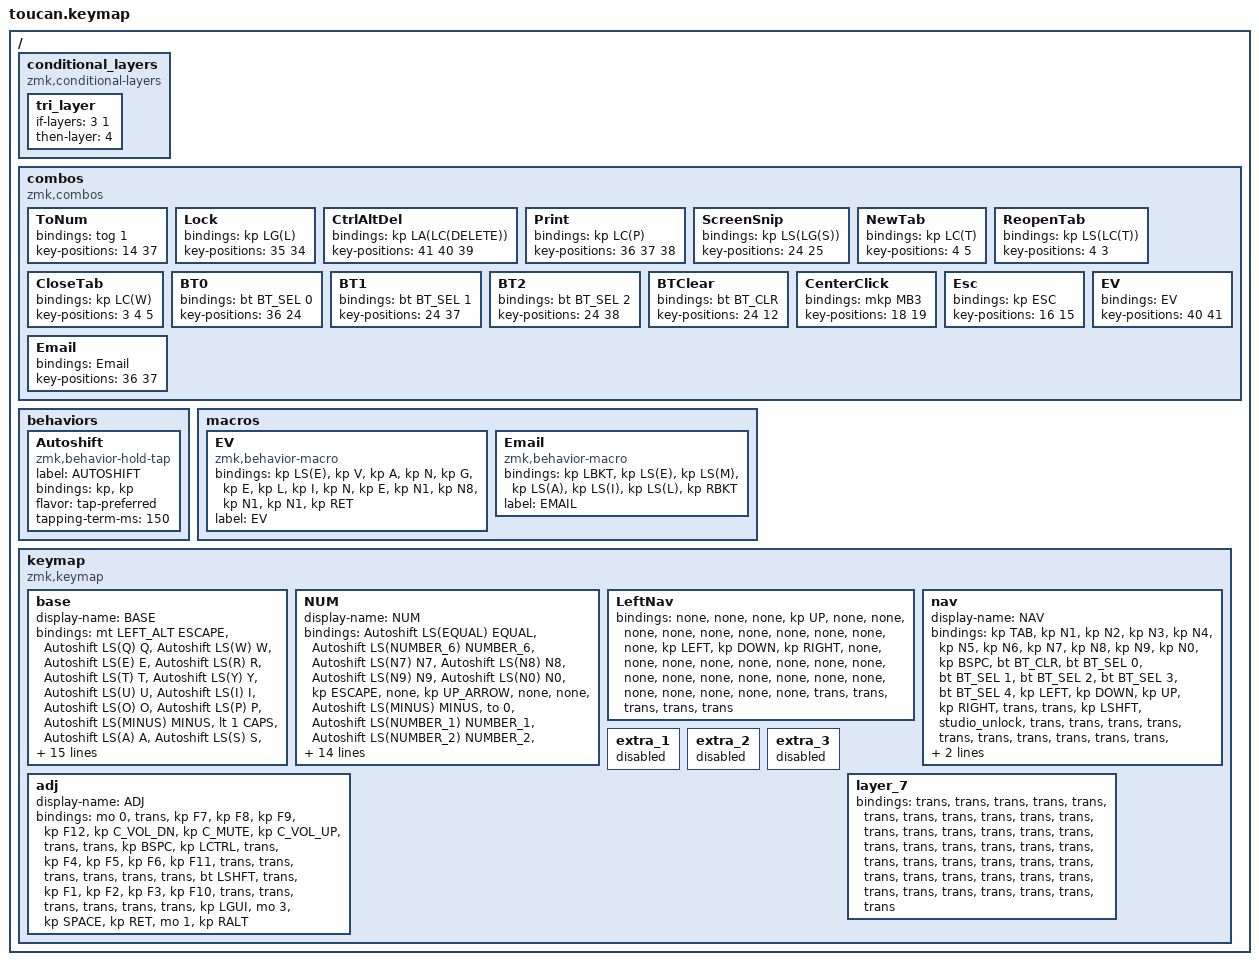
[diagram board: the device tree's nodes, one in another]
#include <behaviors.dtsi>
#include <dt-bindings/zmk/bt.h>
#include <dt-bindings/zmk/keys.h>
#include <dt-bindings/zmk/pointing.h>

#define BASE 0
#define NAV  1
#define SYM  2
#define ADJ  3

/ {
    conditional_layers {
        compatible = "zmk,conditional-layers";

        tri_layer {
            if-layers = <3 1>;
            then-layer = <4>;
        };
    };

    combos {
        compatible = "zmk,combos";

        ToNum {
            bindings = <&tog 1>;
            key-positions = <14 37>;
        };

        Lock {
            bindings = <&kp LG(L)>;
            key-positions = <35 34>;
        };

        CtrlAltDel {
            bindings = <&kp LA(LC(DELETE))>;
            key-positions = <41 40 39>;
        };

        Print {
            bindings = <&kp LC(P)>;
            key-positions = <36 37 38>;
        };

        ScreenSnip {
            bindings = <&kp LS(LG(S))>;
            key-positions = <24 25>;
        };

        NewTab {
            bindings = <&kp LC(T)>;
            key-positions = <4 5>;
        };

        ReopenTab {
            bindings = <&kp LS(LC(T))>;
            key-positions = <4 3>;
        };

        CloseTab {
            bindings = <&kp LC(W)>;
            key-positions = <3 4 5>;
        };

        BT0 {
            bindings = <&bt BT_SEL 0>;
            key-positions = <36 24>;
        };

        BT1 {
            bindings = <&bt BT_SEL 1>;
            key-positions = <24 37>;
        };

        BT2 {
            bindings = <&bt BT_SEL 2>;
            key-positions = <24 38>;
        };

        BTClear {
            bindings = <&bt BT_CLR>;
            key-positions = <24 12>;
        };

        CenterClick {
            bindings = <&mkp MB3>;
            key-positions = <18 19>;
        };

        Esc {
            bindings = <&kp ESC>;
            key-positions = <16 15>;
        };

        EV {
            bindings = <&EV>;
            key-positions = <40 41>;
        };

        Email {
            bindings = <&Email>;
            key-positions = <36 37>;
        };
    };

    behaviors {
        Autoshift: Autoshift {
            compatible = "zmk,behavior-hold-tap";
            label = "AUTOSHIFT";
            bindings = <&kp>, <&kp>;

            #binding-cells = <2>;
            flavor = "tap-preferred";
            tapping-term-ms = <150>;
        };
    };

    macros {
        EV: EV {
            compatible = "zmk,behavior-macro";
            #binding-cells = <0>;
            bindings = <&kp LS(E) &kp V &kp A &kp N &kp G &kp E &kp L &kp I &kp N &kp E &kp N1 &kp N8 &kp N1 &kp N1 &kp RET>;
            label = "EV";
        };

        Email: Email {
            compatible = "zmk,behavior-macro";
            #binding-cells = <0>;
            bindings = <&kp LBKT &kp LS(E) &kp LS(M) &kp LS(A) &kp LS(I) &kp LS(L) &kp RBKT>;
            label = "EMAIL";
        };
    };

    keymap {
        compatible = "zmk,keymap";

        base {
            display-name = "BASE";
            bindings = <
&mt LEFT_ALT ESCAPE  &Autoshift LS(Q) Q  &Autoshift LS(W) W  &Autoshift LS(E) E  &Autoshift LS(R) R  &Autoshift LS(T) T  &Autoshift LS(Y) Y  &Autoshift LS(U) U  &Autoshift LS(I) I  &Autoshift LS(O) O  &Autoshift LS(P) P  &Autoshift LS(MINUS) MINUS  &lt 1 CAPS  &Autoshift LS(A) A  &Autoshift LS(S) S  &Autoshift LS(D) D  &Autoshift LS(F) F  &Autoshift LS(G) G  &Autoshift LS(H) H  &Autoshift LS(J) J  &Autoshift LS(K) K  &Autoshift LS(L) L  &Autoshift LS(SEMI) SEMICOLON  &Autoshift LS(SQT) SQT  &kp LEFT_SHIFT  &Autoshift LS(Z) Z  &Autoshift LS(X) X  &Autoshift LS(C) C  &Autoshift LS(V) V  &Autoshift LS(B) B  &Autoshift LS(N) N  &Autoshift LS(M) M  &Autoshift LS(COMMA) COMMA  &Autoshift LS(DOT) PERIOD  &Autoshift LS(FSLH) SLASH  &sk LC(LEFT_SHIFT)  &kp LCTRL  &kp BACKSPACE  &kp DELETE  &mt LEFT_GUI ENTER  &kp SPACE  &mt LS(TAB) TAB
            >;
        };

        NUM {
            display-name = "NUM";
            bindings = <
&Autoshift LS(EQUAL) EQUAL  &Autoshift LS(NUMBER_6) NUMBER_6  &Autoshift LS(N7) N7  &Autoshift LS(N8) N8  &Autoshift LS(N9) N9  &Autoshift LS(N0) N0  &kp ESCAPE  &none  &kp UP_ARROW  &none  &none  &Autoshift LS(MINUS) MINUS  &to 0  &Autoshift LS(NUMBER_1) NUMBER_1  &Autoshift LS(NUMBER_2) NUMBER_2  &Autoshift LS(NUMBER_3) NUMBER_3  &Autoshift LS(NUMBER_4) NUMBER_4  &Autoshift LS(N5) N5  &none  &kp LEFT  &kp DOWN  &kp RIGHT  &Autoshift LS(SEMICOLON) SEMICOLON  &Autoshift LS(APOSTROPHE) SQT  &kp LSHFT  &mt MINUS SLASH  &mt MINUS SLASH  &mt MINUS SLASH  &mt RIGHT_BRACKET LEFT_BRACKET  &mt RIGHT_BRACKET LEFT_BRACKET  &kp ESC  &none  &Autoshift LS(COMMA) COMMA  &Autoshift LS(PERIOD) PERIOD  &Autoshift LS(SLASH) SLASH  &kp TILDE  &lt 2 PERIOD  &trans  &trans  &trans  &trans  &trans
            >;
        };

        LeftNav {
            bindings = <
&none  &none  &none  &kp UP  &none  &none  &none  &none  &none  &none  &none  &none  &none  &none  &kp LEFT  &kp DOWN  &kp RIGHT  &none  &none  &none  &none  &none  &none  &none  &none  &none  &none  &none  &none  &none  &none  &none  &none  &none  &none  &none  &none  &trans  &trans  &trans  &trans  &trans
            >;
        };

        nav {
            display-name = "NAV";
            bindings = <
&kp TAB  &kp N1  &kp N2  &kp N3  &kp N4  &kp N5  &kp N6  &kp N7  &kp N8  &kp N9  &kp N0  &kp BSPC  &bt BT_CLR  &bt BT_SEL 0  &bt BT_SEL 1  &bt BT_SEL 2  &bt BT_SEL 3  &bt BT_SEL 4  &kp LEFT  &kp DOWN  &kp UP  &kp RIGHT  &trans  &trans  &kp LSHFT  &studio_unlock  &trans  &trans  &trans  &trans  &trans  &trans  &trans  &trans  &trans  &trans  &kp LGUI  &trans  &kp SPACE  &kp RET  &trans  &kp RALT
            >;
        };

        adj {
            display-name = "ADJ";
            bindings = <
&mo 0  &trans  &kp F7  &kp F8  &kp F9  &kp F12  &kp C_VOL_DN  &kp C_MUTE  &kp C_VOL_UP  &trans  &trans  &kp BSPC  &kp LCTRL  &trans  &kp F4  &kp F5  &kp F6  &kp F11  &trans  &trans  &trans  &trans  &trans  &trans  &bt LSHFT  &trans  &kp F1  &kp F2  &kp F3  &kp F10  &trans  &trans  &trans  &trans  &trans  &trans  &kp LGUI  &mo 3  &kp SPACE  &kp RET  &mo 1  &kp RALT
            >;
        };

        extra_1 { status = "reserved"; };

        extra_2 { status = "reserved"; };

        extra_3 { status = "reserved"; };

        layer_7 {
            bindings = <
&trans  &trans  &trans  &trans  &trans  &trans  &trans  &trans  &trans  &trans  &trans  &trans  &trans  &trans  &trans  &trans  &trans  &trans  &trans  &trans  &trans  &trans  &trans  &trans  &trans  &trans  &trans  &trans  &trans  &trans  &trans  &trans  &trans  &trans  &trans  &trans  &trans  &trans  &trans  &trans  &trans  &trans
            >;
        };
    };
};
